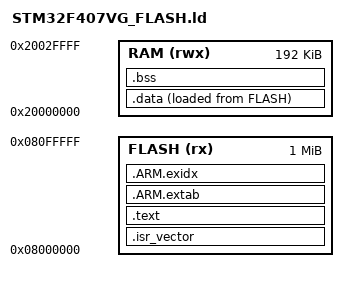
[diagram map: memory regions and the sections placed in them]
/* STM32F407VGT6: 1 MiB internal FLASH, 192 KiB contiguous SRAM1+SRAM2.
 * CCM RAM (0x10000000) is intentionally unused by this small demo.
 */
ENTRY(Reset_Handler)

MEMORY
{
    FLASH (rx)  : ORIGIN = 0x08000000, LENGTH = 1024K
    RAM   (rwx) : ORIGIN = 0x20000000, LENGTH = 192K
}

_estack = ORIGIN(RAM) + LENGTH(RAM);

SECTIONS
{
    .isr_vector :
    {
        . = ALIGN(4);
        KEEP(*(.isr_vector))
        . = ALIGN(4);
    } > FLASH

    .text :
    {
        . = ALIGN(4);
        *(.text*)
        *(.rodata*)
        . = ALIGN(4);
        _etext = .;
    } > FLASH

    .ARM.extab :
    {
        *(.ARM.extab* .gnu.linkonce.armextab.*)
    } > FLASH

    .ARM.exidx :
    {
        __exidx_start = .;
        *(.ARM.exidx* .gnu.linkonce.armexidx.*)
        __exidx_end = .;
    } > FLASH

    _sidata = LOADADDR(.data);
    .data :
    {
        . = ALIGN(4);
        _sdata = .;
        *(.data*)
        . = ALIGN(4);
        _edata = .;
    } > RAM AT> FLASH

    .bss (NOLOAD) :
    {
        . = ALIGN(4);
        _sbss = .;
        *(.bss*)
        *(COMMON)
        . = ALIGN(4);
        _ebss = .;
    } > RAM

    . = ALIGN(8);
    _end = .;

    /DISCARD/ :
    {
        *(.note.GNU-stack)
        *(.comment)
        *(.eh_frame*)
    }
}
